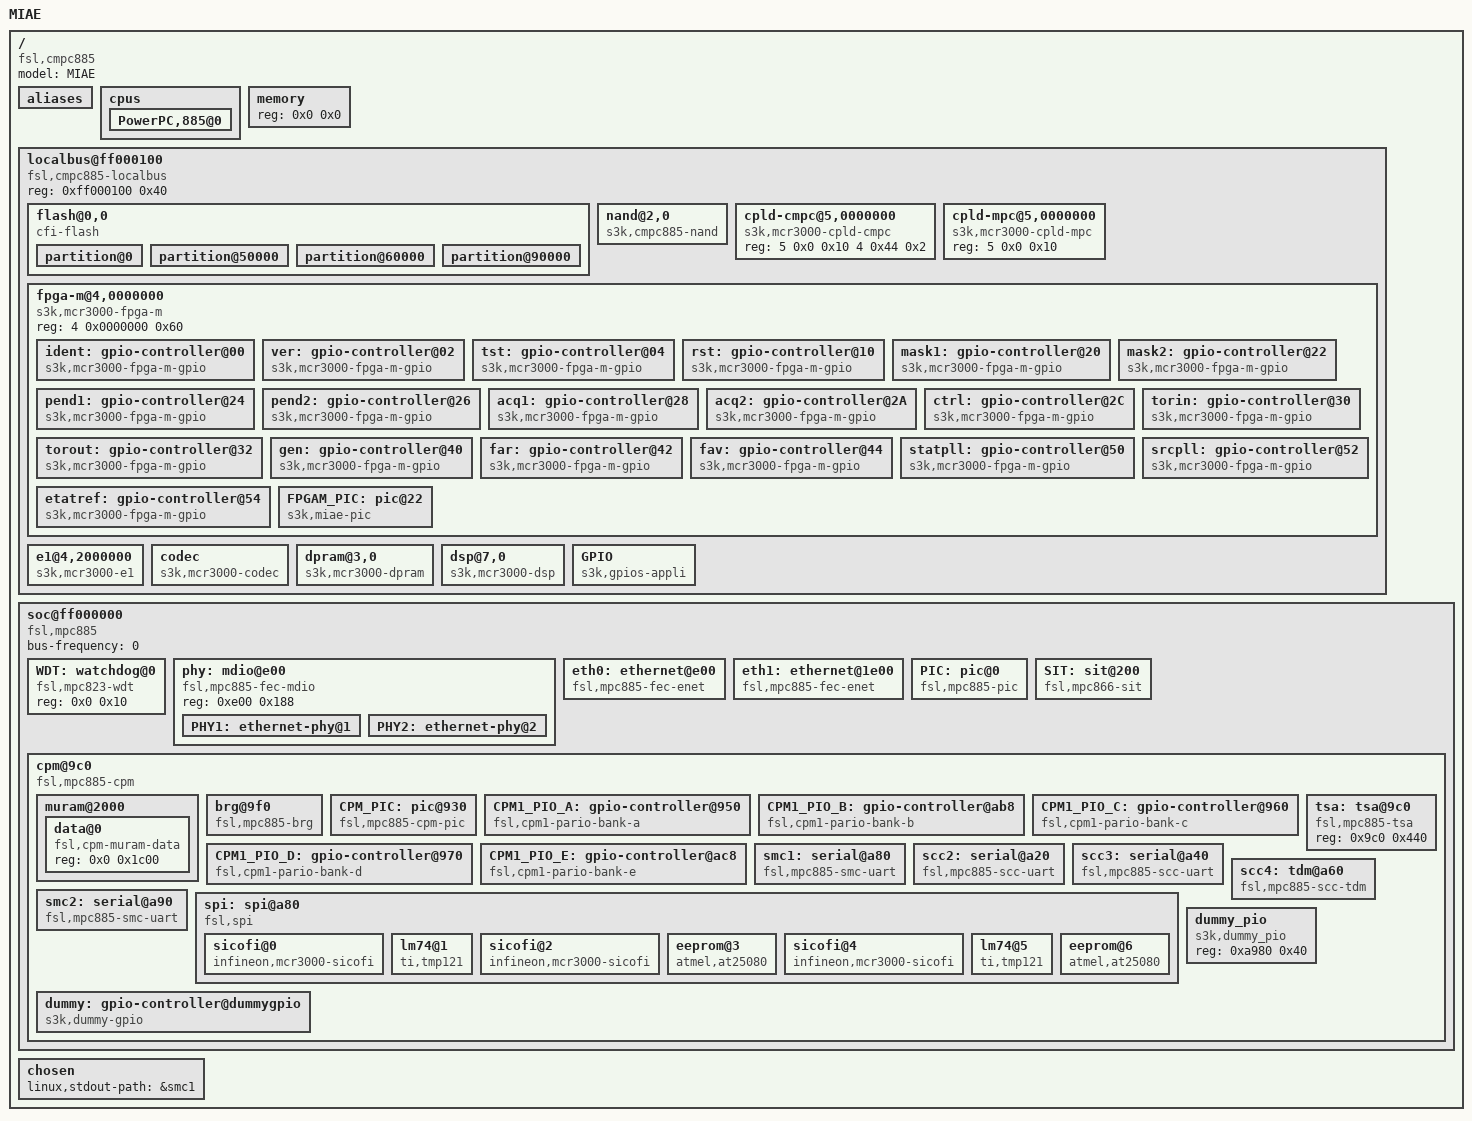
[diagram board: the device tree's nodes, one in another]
/*
 * MIA ethernet Device Tree Source
 *
 * Copyright 2011 CSSI, Inc
 */

/dts-v1/;

/ {
	model = "MIAE";
//	model = "MCR3000_2G";
	compatible = "fsl,cmpc885", "fsl,mod885";
	#address-cells = <1>;
	#size-cells = <1>;

	aliases {
		ethernet0 = &eth0;
		ethernet1 = &eth1;
		mdio = &phy;
		serial0 = &smc1;
	};

	cpus {
		#address-cells = <1>;
		#size-cells = <0>;

		PowerPC,885@0 {
			device_type = "cpu";
			reg = <0x0>;
			d-cache-line-size = <16>;	// 16 bytes
			i-cache-line-size = <16>;	// 16 bytes
			d-cache-size = <8192>;
			i-cache-size = <8192>;
			timebase-frequency = <0>;
			bus-frequency = <0>;
			clock-frequency = <0>;
			interrupts = <15 2>;		// decrementer interrupt
			interrupt-parent = <&PIC>;
		};
	};

	memory {
		device_type = "memory";
		reg = <0x0 0x0>;			// defined by U-BOOT
	};

	localbus@ff000100 {
		compatible = "fsl,cmpc885-localbus", "fsl,pq1-localbus";
		#address-cells = <2>;
		#size-cells = <1>;
		reg = <0xff000100 0x40>;		// ORx and BRx register

		ranges = <0 0x0 0x40000000 0x00400000 // Boot Flash
			  1 0x0 0x00000000 0x08000000 // SDRAM
			  2 0x0 0xc0000000 0x00008000 // Nand Flash
			  3 0x0 0xe0000000 0x00010000 // DPRAM
			  4 0x0 0xd0000000 0x10000000 // Periphs
			  5 0x0 0xc8000000 0x00008000 // CPLD
			  6 0x0 0x80000000 0x00008000 // mezzanine
			  7 0x0 0xf0000000 0x00008000>; // DSP

		flash@0,0 {
			#address-cells = <1>;
			#size-cells = <1>;
			compatible = "cfi-flash";
			reg = <0x0 0x00000000 0x400000>;
			bank-width = <2>;
			device-width = <2>;
			partition@0 {
				label = "boot";
				reg = <0x0 0x50000>;
			};
			partition@50000 {
				label = "env";
				reg = <0x50000 0x10000>;
			};
			partition@60000 {
				label = "blob";
				reg = <0x60000 0x30000>;
			};
			partition@90000 {
				label = "kernel";
				reg = <0x90000 0x370000>;
			};
		};

		nand@2,0 {
			compatible = "s3k,cmpc885-nand";
			reg = <2 0x0 0x01>;
			#address-cells = <1>;
			#size-cells = <1>;
			gpios = <&CPM1_PIO_D 12 1 	// CLE
				 &CPM1_PIO_D 13 1	// ALE
				 &CPM1_PIO_D 15 1>;	// NCE
		};

		cpld-cmpc@5,0000000 { // Driver KNL
			#address-cells = <1>;
			#size-cells = <1>;
			compatible = "s3k,mcr3000-cpld-cmpc";
			reg = <5 0x0 0x10 4 0x44 0x2>;
		};
		
		cpld-mpc@5,0000000 { // Driver LDB (deviendra obsolete)
			#address-cells = <1>;
			#size-cells = <1>;
			compatible = "s3k,mcr3000-cpld-mpc";
			reg = <5 0x0 0x10>;
		};
		
		fpga-m@4,0000000 { // Driver LDB (deviendra peut etre obsolete)
			#address-cells = <1>;
			#size-cells = <1>;
			compatible = "s3k,mcr3000-fpga-m";
			reg = <4 0x0000000 0x60>;
			ranges = <0 4 0x0000000 0x60>;
			ident: gpio-controller@00 {
				#gpio-cells = <2>;
				compatible = "s3k,mcr3000-fpga-m-gpio";
				reg = <0x00 2>;
				gpio-controller;
			};
			ver: gpio-controller@02 {
				#gpio-cells = <2>;
				compatible = "s3k,mcr3000-fpga-m-gpio";
				reg = <0x02 2>;
				gpio-controller;
			};
			tst: gpio-controller@04 {
				#gpio-cells = <2>;
				compatible = "s3k,mcr3000-fpga-m-gpio";
				reg = <0x04 2>;
				gpio-controller;
			};
			rst: gpio-controller@10 {
				#gpio-cells = <2>;
				compatible = "s3k,mcr3000-fpga-m-gpio";
				reg = <0x10 2>;
				gpio-controller;
			};
			mask1: gpio-controller@20 {
				#gpio-cells = <2>;
				compatible = "s3k,mcr3000-fpga-m-gpio";
				reg = <0x20 2>;
				gpio-controller;
			};
			mask2: gpio-controller@22 {
				#gpio-cells = <2>;
				compatible = "s3k,mcr3000-fpga-m-gpio";
				reg = <0x22 2>;
				gpio-controller;
			};
			pend1: gpio-controller@24 {
				#gpio-cells = <2>;
				compatible = "s3k,mcr3000-fpga-m-gpio";
				reg = <0x24 2>;
				gpio-controller;
			};
			pend2: gpio-controller@26 {
				#gpio-cells = <2>;
				compatible = "s3k,mcr3000-fpga-m-gpio";
				reg = <0x26 2>;
				gpio-controller;
			};
			acq1: gpio-controller@28 {
				#gpio-cells = <2>;
				compatible = "s3k,mcr3000-fpga-m-gpio";
				reg = <0x28 2>;
				gpio-controller;
			};
			acq2: gpio-controller@2A {
				#gpio-cells = <2>;
				compatible = "s3k,mcr3000-fpga-m-gpio";
				reg = <0x2A 2>;
				gpio-controller;
			};
			ctrl: gpio-controller@2C {
				#gpio-cells = <2>;
				compatible = "s3k,mcr3000-fpga-m-gpio";
				reg = <0x2C 2>;
				gpio-controller;
			};
			torin: gpio-controller@30 {
				#gpio-cells = <2>;
				compatible = "s3k,mcr3000-fpga-m-gpio";
				reg = <0x30 2>;
				interrupts = <255 255 2 3 4 5 6 7 8 9 10 11 12 13 14 15>;
				interrupt-parent = <&FPGAM_PIC>;
				gpio-controller;
			};
			torout: gpio-controller@32 {
				#gpio-cells = <2>;
				compatible = "s3k,mcr3000-fpga-m-gpio";
				reg = <0x32 2>;
				gpio-controller;
			};
			gen: gpio-controller@40 {
				#gpio-cells = <2>;
				compatible = "s3k,mcr3000-fpga-m-gpio";
				reg = <0x40 2>;
				gpio-controller;
			};
			far: gpio-controller@42 {
				#gpio-cells = <2>;
				compatible = "s3k,mcr3000-fpga-m-gpio";
				reg = <0x42 2>;
				gpio-controller;
			};
			fav: gpio-controller@44 {
				#gpio-cells = <2>;
				compatible = "s3k,mcr3000-fpga-m-gpio";
				reg = <0x44 2>;
				gpio-controller;
			};
			statpll: gpio-controller@50 {
				#gpio-cells = <2>;
				compatible = "s3k,mcr3000-fpga-m-gpio";
				reg = <0x50 2>;
				gpio-controller;
			};
			srcpll: gpio-controller@52 {
				#gpio-cells = <2>;
				compatible = "s3k,mcr3000-fpga-m-gpio";
				reg = <0x52 2>;
				gpio-controller;
			};
			etatref: gpio-controller@54 {
				#gpio-cells = <2>;
				compatible = "s3k,mcr3000-fpga-m-gpio";
				reg = <0x54 2>;
//				interrupts = <255 255 255 255 255 255 255 255 255 255 255 255 255 255 255 255>;
//				interrupt-parent = <&FPGAM_PIC>;
				gpio-controller;
			};
			FPGAM_PIC: pic@22 {
				interrupt-controller;
				#address-cells = <0>;
				#interrupt-cells = <1>;
				interrupts = <6 1>;
				interrupt-parent = <&PIC>;
				reg = <0x00 0x60>;	// Mappage registres FPGAF
				compatible = "s3k,miae-pic";
//				compatible = "s3k,mcr3000_2g-pic";
			};
		};
		
//		fpga@4,1000000 {
//			#address-cells = <1>;
//			#size-cells = <1>;
//			compatible = "s3k,mcr3000-fpga";
//			reg = <4 0x1000000 0x0200 6 0x0 0x0002>;
//			interrupts = <6 1>;
//			interrupt-parent = <&PIC>;
//		};

		e1@4,2000000 {
			#address-cells = <1>;
			#size-cells = <1>;
			compatible = "s3k,mcr3000-e1";
			reg = <4 0x2000000 0xFF>;
			interrupts = <8 1>;
			interrupt-parent = <&PIC>;
		};
		
//		mtsl@4,3000000 {
//			#address-cells = <1>;
//			#size-cells = <1>;
//			compatible = "s3k,mcr3000-mtsl";
//			reg = <4 0x3000000 0xFFFF>;
//		};

		codec {
			compatible = "s3k,mcr3000-codec";
		};

//		alarmes {
//			compatible = "s3k,mcr3000-alarmes";
//			gpios = <&alin 13 1 	// ACQ_ALRM
//				&alout 15 1	// ALRM_MAJ
//				&alout 14 1>;	// ALRM_MIN
//		};
		
		dpram@3,0 {
			#address-cells = <1>;
			#size-cells = <1>;
			compatible = "s3k,mcr3000-dpram";
			reg = <3 0x0 0x10000>;
			interrupts = <4 1>;
			interrupt-parent = <&PIC>;
		};

		dsp@7,0 {
			#address-cells = <1>;
			#size-cells = <1>;
			compatible = "s3k,mcr3000-dsp";
			reg = <7 0x0 0x0008>;
			interrupts = <0 1>;
			interrupt-parent = <&FPGAM_PIC>;
		};

		GPIO {
			/* 0 = sortie initialisee active */
			/* 1 = entree */
			/* 2 = sortie initialisee inactive */
			compatible = "s3k,gpios-appli";
			gpios = <&torin  15 1	// TOR in 1
//				&torin   14 1	// TOR in 2
//				&torin   13 1	// TOR in 3
				&rst   12 2	// TOR in 2
				&rst   3 2	// TOR in 3
				&torin   12 1	// TOR in 4
				&torin   11 1	// TOR in 5
				&torin   10 1	// TOR in 6
				&torin    9 1	// TOR in 7
				&torin    8 1	// TOR in 8
				&torin    7 1	// TOR in 9
				&torin    6 1	// TOR in 10
				&torin    5 1	// TOR in 11
				&torin    4 1	// TOR res
				&torin    3 1	// TOR res
				&torin    2 1	// TOR res
				&torin    1 1	// TOR res
				&torin    0 1	// TOR res
				&far     15 1	// Alternat BP
				&far     13 1	// Alternat 1
				&far     14 1	// Alternat 2
				&far     12 1	// Alternat Combine
				&fav     11 1	// Alternat µMain1
				&fav     15 1	// Alternat µMain2
				&fav      9 1	// Alternat µCasque1
				&fav     13 1	// Alternat µCasque2
				&gen     14 1	// Pres Alim 24V
				&etatref 15 1	// Synchro E1
				&etatref 14 1	// Synchro S0
				&etatref 13 1	// Alternat res
				&etatref 12 1	// Alternat res
				&etatref 11 1	// Alternat res
				&etatref 10 1	// Alternat res
				&etatref  9 1>;	// Alternat res
			names = "tor_in_1",
				"tor_in_2",
				"tor_in_3",
				"tor_in_4",
				"tor_in_5",
				"tor_in_6",
				"tor_in_7",
				"tor_in_8",
				"tor_in_9",
				"tor_in_10",
				"tor_in_11",
				"it1_res_1",
				"it1_res_2",
				"it1_res_3",
				"it1_res_4",
				"it1_res_5",
				"alt_poussoir",
				"alt_interphone",
				"alt_pedale",
				"alt_combine",
				"alt_main_1",
				"alt_main_2",
				"alt_casque_1",
				"alt_casque_2",
				"it2_res_1",
				"it2_res_2",
				"it2_res_3",
				"it2_res_4",
				"it2_res_5",
				"it2_res_6",
				"it2_res_7",
				"it2_res_8";
		};
	};

	soc@ff000000 {
		compatible = "fsl,mpc885", "fsl,pq1-soc";
		#address-cells = <1>;
		#size-cells = <1>;
		device_type = "soc";
		ranges = <0x0 0xff000000 0x28000>;
		bus-frequency = <0>;

		WDT: watchdog@0 {
			compatible = "fsl,mpc823-wdt";
			reg = <0x0 0x10>;
		};

		phy: mdio@e00 {
			compatible = "fsl,mpc885-fec-mdio", "fsl,pq1-fec-mdio";
			reg = <0xe00 0x188>;
			#address-cells = <1>;
			#size-cells = <0>;

			PHY1: ethernet-phy@1 {
				interrupts = <2 1>;
				interrupt-parent = <&PIC>;
				reg = <0x1>;
				device_type = "ethernet-phy";
			};

			PHY2: ethernet-phy@2 {
				interrupts = <2 1>;
				interrupt-parent = <&PIC>;
				reg = <0x2>;
				device_type = "ethernet-phy";
			};
		};

		eth0: ethernet@e00 {
			device_type = "network";
			compatible = "fsl,mpc885-fec-enet", "fsl,pq1-fec-enet";
			reg = <0xe00 0x188>;
			local-mac-address = [ 00 00 00 00 00 00 ];
			interrupts = <3 1>;
			interrupt-parent = <&PIC>;
			phy-handle = <&PHY1>;
			linux,network-index = <0>;
		};

		eth1: ethernet@1e00 {
			device_type = "network";
			compatible = "fsl,mpc885-fec-enet", "fsl,pq1-fec-enet";
			reg = <0x1e00 0x188>;
			local-mac-address = [ 00 00 00 00 00 00 ];
			interrupts = <7 1>;
			interrupt-parent = <&PIC>;
			phy-handle = <&PHY2>;
			linux,network-index = <1>;
		};

		PIC: pic@0 {
			interrupt-controller;
			#interrupt-cells = <2>;
			reg = <0x0 0x24>;
			compatible = "fsl,mpc885-pic", "fsl,pq1-pic";
		};

		SIT: sit@200 {
			compatible = "fsl,mpc866-sit", "fsl,pq1-sit";
			reg = <0x200 0x80>;
			interrupts = <11 1>;
			interrupt-parent = <&PIC>;
		};

		cpm@9c0 {
			#address-cells = <1>;
			#size-cells = <1>;
			compatible = "fsl,mpc885-cpm", "fsl,cpm1";
			ranges;
			reg = <0x9c0 0x40>;
			brg-frequency = <0>;
			interrupts = <0>;	// cpm error interrupt
			interrupt-parent = <&CPM_PIC>;

			muram@2000 {
				#address-cells = <1>;
				#size-cells = <1>;
				ranges = <0x0 0x2000 0x2000>;

				data@0 {
					compatible = "fsl,cpm-muram-data";
					reg = <0x0 0x1c00>;
				};
			};

			brg@9f0 {
				compatible = "fsl,mpc885-brg", "fsl,cpm1-brg", "fsl,cpm-brg";
				reg = <0x9f0 0x10>;
				clock-frequency = <0>;
			};

			CPM_PIC: pic@930 {
				interrupt-controller;
				#address-cells = <0>;
				#interrupt-cells = <1>;
				interrupts = <5 2 0 2>;
				interrupt-parent = <&PIC>;
				reg = <0x930 0x20>;
				compatible = "fsl,mpc885-cpm-pic", "fsl,cpm1-pic";
			};

			CPM1_PIO_A: gpio-controller@950 {
				#gpio-cells = <2>;
				compatible = "fsl,cpm1-pario-bank-a";
				reg = <0x950 0x10>;
				gpio-controller;
			};
		
			CPM1_PIO_B: gpio-controller@ab8 {
				#gpio-cells = <2>;
				compatible = "fsl,cpm1-pario-bank-b";
				reg = <0xab8 0x10>;
				gpio-controller;
			};
		
			CPM1_PIO_C: gpio-controller@960 {
				#gpio-cells = <2>;
				compatible = "fsl,cpm1-pario-bank-c";
				reg = <0x960 0x10>;
				interrupts = <0 0 0 0 1 2 6 9 10 11 14 15 23 24 26 31>;
				interrupt-parent = <&CPM_PIC>;
				gpio-controller;
			};
		
			CPM1_PIO_D: gpio-controller@970 {
				#gpio-cells = <2>;
				compatible = "fsl,cpm1-pario-bank-d";
				reg = <0x970 0x10>;
				gpio-controller;
			};
		
			CPM1_PIO_E: gpio-controller@ac8 {
				#gpio-cells = <2>;
				compatible = "fsl,cpm1-pario-bank-e";
				reg = <0xac8 0x18>;
				gpio-controller;
			};
			
			tsa: tsa@9c0 {
				compatible = "fsl,mpc885-tsa", "fsl,cpm1-tsa";
				reg = <0x9c0 0x440>;
			};

			smc1: serial@a80 {
				device_type = "serial";
				compatible = "fsl,mpc885-smc-uart", "fsl,cpm1-smc-uart";
				reg = <0xa80 0x10 0x3e80 0x40>;
				interrupts = <4>;
				interrupt-parent = <&CPM_PIC>;
				fsl,cpm-brg = <4>;
				fsl,cpm-command = <0x90>;
			};

			scc2: serial@a20 {
				device_type = "serial";
				compatible = "fsl,mpc885-scc-uart", "fsl,cpm1-scc-uart";
				reg = <0xa20 0x20 0x3d00 0x80>;
				interrupts = <29>;
				interrupt-parent = <&CPM_PIC>;
				fsl,cpm-brg = <1>;
				fsl,cpm-command = <0x40>;
			};

			scc3: serial@a40 {
				device_type = "serial";
				compatible = "fsl,mpc885-scc-uart", "fsl,cpm1-scc-uart";
				reg = <0xa40 0x20 0x3e00 0x80>;
				interrupts = <28>;
				interrupt-parent = <&CPM_PIC>;
				fsl,cpm-brg = <2>;
				fsl,cpm-command = <0x80>;
			};

			scc4: tdm@a60 {
				device_type = "tdm";
				compatible = "fsl,mpc885-scc-tdm", "fsl,cpm1-scc-tdm";
				reg = <0xa60 0x20 0x3f00 0x80>;
				interrupts = <27>;
				interrupt-parent = <&CPM_PIC>;
				fsl,cpm-command = <0xc0>;
			};

			smc2: serial@a90 {
				device_type = "serial";
				compatible = "fsl,mpc885-smc-uart", "fsl,cpm1-smc-uart";
				reg = <0xa90 0x10 0x3f80 0x40>;
				interrupts = <3>;
				interrupt-parent = <&CPM_PIC>;
				fsl,cpm-brg = <3>; /* normalement mettre une clock venant du FPGA */
				fsl,cpm-command = <0xd0>;
			};

			spi: spi@a80 {
				#address-cells = <1>;
				#size-cells = <0>;
				cell-index = <0>;
				compatible = "fsl,spi", "fsl,cpm1-spi";
				reg = <0xa80 0x30 0x1d80 0x30>;
				interrupts = <5>;
				interrupt-parent = <&CPM_PIC>;
				mode = "cpu";
				gpios = <&CPM1_PIO_C 4 1	/* SICOFI 1 */
					 &CPM1_PIO_B 23 1	/* TEMP MCR */
					 &CPM1_PIO_C 8 1	/* SICOFI 2 */
					 &CPM1_PIO_C 12 1	/* EEPROM MCR3000 2G*/
					 &CPM1_PIO_D 6 1	/* SICOFI 3 */
					 &CPM1_PIO_B 14 1	/* TEMP MPC885 */
					 &CPM1_PIO_B 21 1>;	/* EEPROM CMPC885 */
				sicofi@0 {
					compatible = "infineon,mcr3000-sicofi";
					spi-max-frequency = <1000000>;
					reg = <0>;
					spi-cs-high;
					spi-cpha;
					spi-troll;
				};
				lm74@1 {
					compatible = "ti,tmp121", "ns,lm74";
					spi-max-frequency = <1000000>;
					reg = <1>;
					spi-cs-high;
				};
				sicofi@2 {
					compatible = "infineon,mcr3000-sicofi";
					spi-max-frequency = <1000000>;
					reg = <2>;
					spi-cs-high;
					spi-cpha;
					spi-troll;
				};
				eeprom@3 {
					compatible = "atmel,at25080", "cs,eeprom";
					spi-max-frequency = <1000000>;
					reg = <3>;
					spi-cs-high;
				};
				sicofi@4 {
					compatible = "infineon,mcr3000-sicofi";
					spi-max-frequency = <1000000>;
					reg = <4>;
					spi-cs-high;
					spi-cpha;
					spi-troll;
				};
				lm74@5 {
					compatible = "ti,tmp121", "ns,lm74";
					spi-max-frequency = <1000000>;
					reg = <5>;
					spi-cs-high;
				};
				eeprom@6 {
					compatible = "atmel,at25080", "cs,eeprom";
					spi-max-frequency = <1000000>;
					reg = <6>;
					spi-cs-high;
				};
				
			};
			
			dummy_pio {
				compatible = "s3k,dummy_pio";
				reg = <0xa980 0x40>;
			};

			dummy: gpio-controller@dummygpio {
				#gpio-cells = <2>;
				compatible = "s3k,dummy-gpio";
				reg = <0x2 0x1>; /* necessaire mais non utilise */
				gpio-controller;
			};
		};
			
/*		crypto@20000 {
			compatible = "fsl,sec2.0";
			reg = <0x20000 0x8000>;
			interrupts = <1 1>;
			interrupt-parent = <&PIC>;
			fsl,num-channels = <1>;
			fsl,channel-fifo-len = <24>;
			fsl,exec-units-mask = <0x4c>;
			fsl,descriptor-types-mask = <0x301f>;
		};
*/	};

	chosen {
		linux,stdout-path = &smc1;
	};
};
